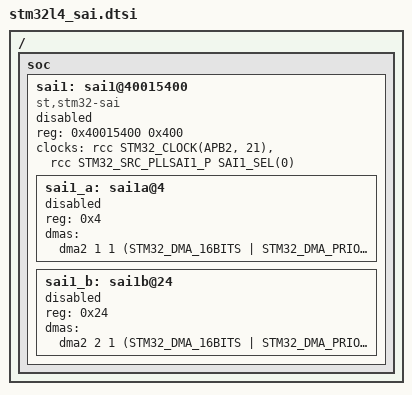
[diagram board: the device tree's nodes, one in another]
/*
 * Copyright (c) 2025 Mario Paja
 *
 * SPDX-License-Identifier: Apache-2.0
 */

/ {
	soc {
		sai1: sai1@40015400 {
			compatible = "st,stm32-sai";
			#address-cells = <1>;
			#size-cells = <0>;
			reg = <0x40015400 0x400>;
			clocks = <&rcc STM32_CLOCK(APB2, 21)>,
				 <&rcc STM32_SRC_PLLSAI1_P SAI1_SEL(0)>;
			status = "disabled";

			sai1_a: sai1a@4 {
				reg = <0x4>;
				dmas = <&dma2 1 1 (STM32_DMA_16BITS | STM32_DMA_PRIORITY_HIGH)>;
				#address-cells = <1>;
				#size-cells = <0>;
				status = "disabled";
			};

			sai1_b: sai1b@24 {
				reg = <0x24>;
				dmas = <&dma2 2 1 (STM32_DMA_16BITS | STM32_DMA_PRIORITY_HIGH)>;
				#address-cells = <1>;
				#size-cells = <0>;
				status = "disabled";
			};
		};
	};
};
